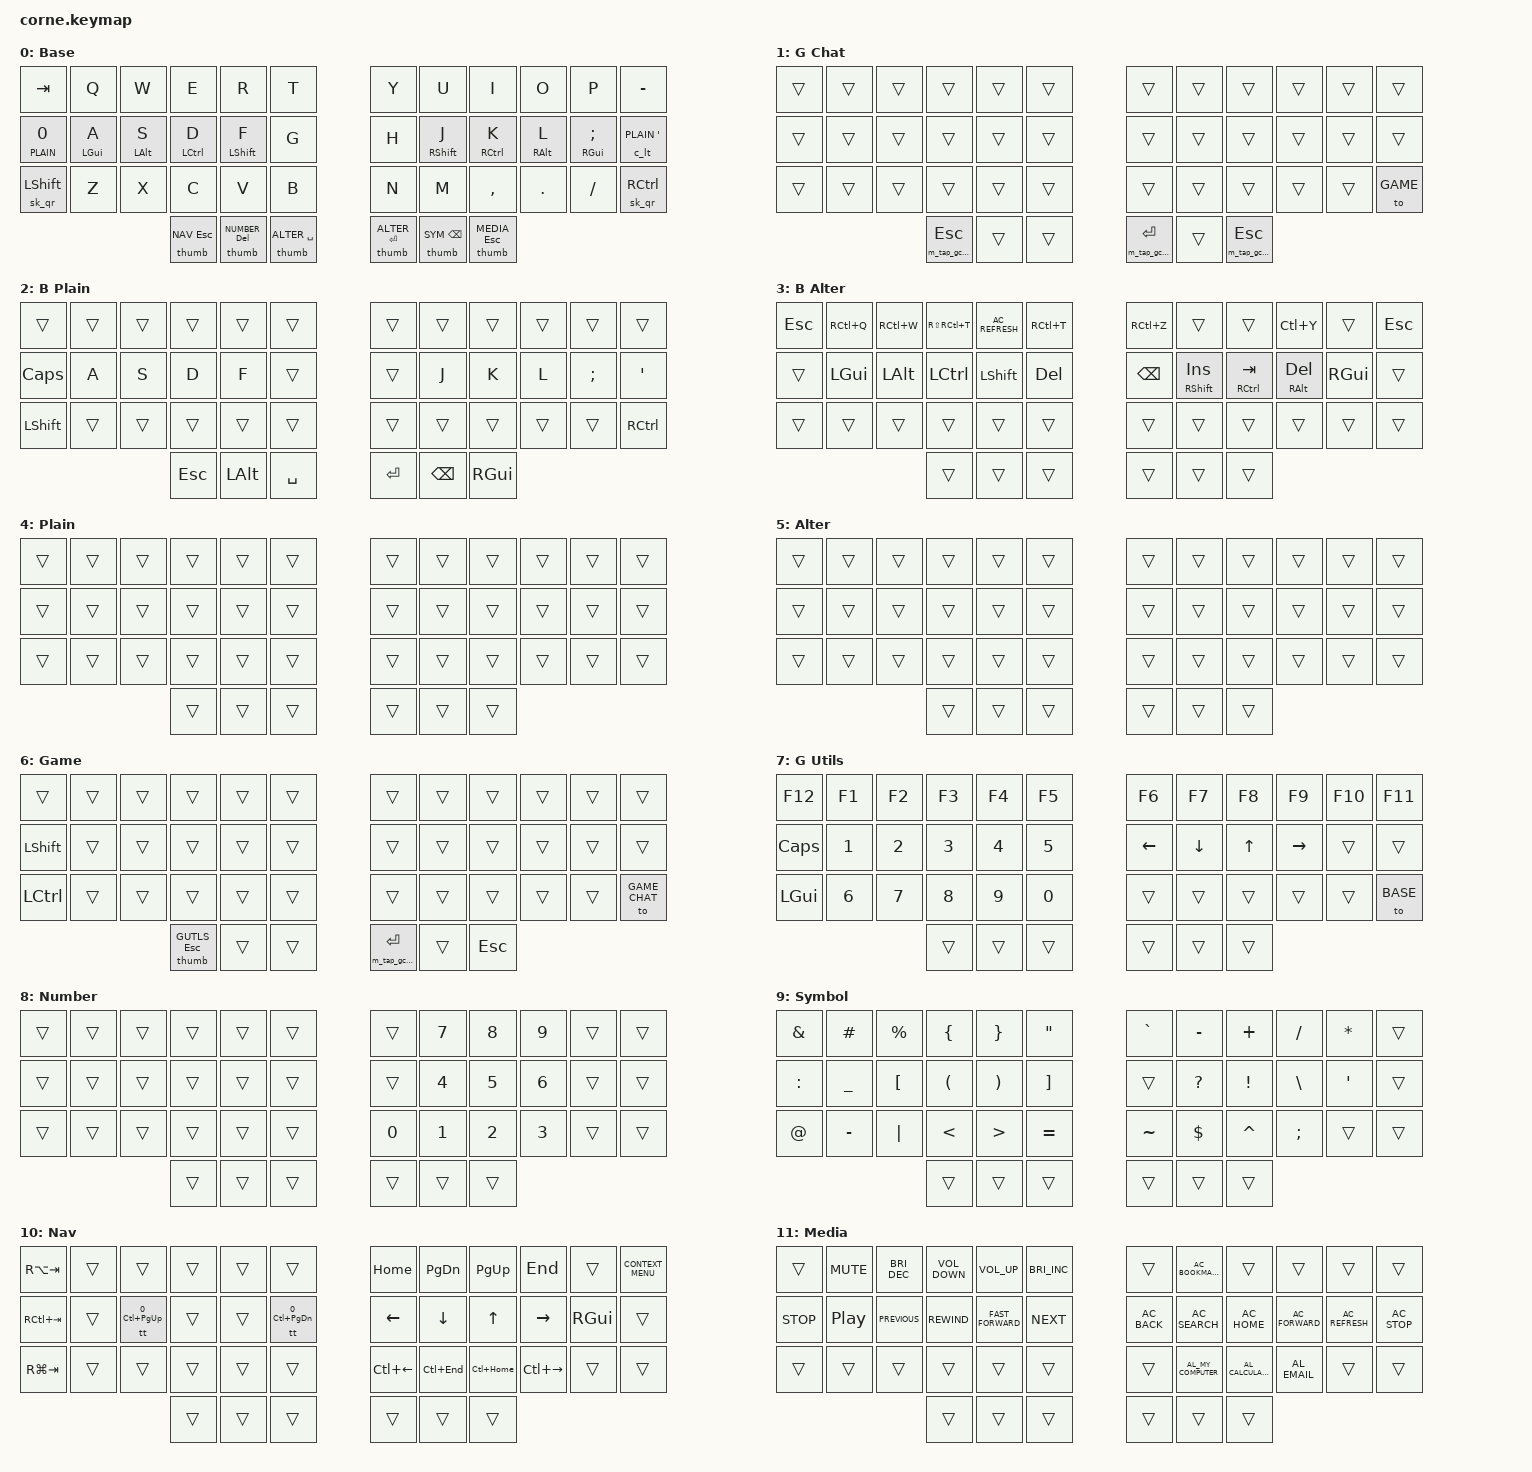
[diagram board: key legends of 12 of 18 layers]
/*
 * Copyright (c) 2020 The ZMK Contributors
 *
 * SPDX-License-Identifier: MIT
 */

#include <behaviors.dtsi>
#include <dt-bindings/zmk/keys.h>
#include <dt-bindings/zmk/bt.h>

#include "includes/constants.dtsi"
#include "includes/helpers.dtsi"

#include "fragments/macros.dtsi"
#include "fragments/behaviors.dtsi"
#include "fragments/combos.dtsi"
#include "fragments/conditional_layers.dtsi"

// Keymap template
//         template_layer {
//             display-name = "Temp";
// // -----------------------------------------------------------------------------------
// // |  ___ | ___ | ___ | ___ | ___ | ___ |       | ___ | ___ | ___ | ___ | ___ | ___  |
// // |  ___ | ___ | ___ | ___ | ___ | ___ |       | ___ | ___ | ___ | ___ | ___ | ___  |
// // |  ___ | ___ | ___ | ___ | ___ | ___ |       | ___ | ___ | ___ | ___ | ___ | ___  |
// //                    | ___ | ___ | ___ |       | ___ | ___ | ___ |
//             bindings = <
// &trans                 &trans                 &trans                 &trans                 &trans                 &trans                           &trans                 &trans                 &trans                 &trans                 &trans                 &trans
// &trans                 &trans                 &trans                 &trans                 &trans                 &trans                           &trans                 &trans                 &trans                 &trans                 &trans                 &trans
// &trans                 &trans                 &trans                 &trans                 &trans                 &trans                           &trans                 &trans                 &trans                 &trans                 &trans                 &trans
//                                                                      &trans                 &trans                 &trans                           &trans                 &trans                 &trans
//             >;
//         };

/ {
    keymap {
        compatible = "zmk,keymap";

        default_layer {
            display-name = "Base";
// -----------------------------------------------------------------------------------
// |  TAB |  Q  |  W  |  E  |  R  |  T  |       |  Y  |  U  |  I  |  O  |  P  |  -   |
// |  CAP |  A  |  S  |  D  |  F  |  G  |       |  H  |  J  |  K  |  L  |  ;  |  '   |
// |  SFT |  Z  |  X  |  C  |  V  |  B  |       |  N  |  M  |  ,  |  .  |  /  | CTL  |
//                    | ESC | DEL | SPC |       | RET | BSP | ESC |
            bindings = <
&kp TAB                &kp Q                  &kp W                  &kp E                  &kp R                  &kp T                            &kp Y                  &kp U                  &kp I                  &kp O                  &kp P                  &kp MINUS
&lt_cw PLAIN 0         &hrm_l LGUI A          &hrm_l LALT S          &hrm_l LCTRL D         &hrm_li LSHFT F        &kp G                            &kp H                  &hrm_ri RSHFT J        &hrm_r RCTRL K         &hrm_r RALT L          &hrm_r RGUI SEMICOLON  &c_lt PLAIN SINGLE_QUOTE
&sk_qr LEFT_SHIFT      &kp Z                  &kp X                  &kp C                  &kp V                  &kp B                            &kp N                  &kp M                  &kp COMMA              &kp PERIOD             &kp SLASH              &sk_qr RIGHT_CONTROL
                                                                     &thumb NAV ESCAPE      &thumb NUMBER DELETE   &thumb ALTER SPACE               &thumb ALTER RETURN    &thumb SYM BACKSPACE   &thumb MEDIA ESCAPE
            >;
        };

        game_chat_layer {
            display-name = "G Chat";
// -----------------------------------------------------------------------------------
// |  ___ | ___ | ___ | ___ | ___ | ___ |       | ___ | ___ | ___ | ___ | ___ | ___  |
// |  ___ | ___ | ___ | ___ | ___ | ___ |       | ___ | ___ | ___ | ___ | ___ | ___  |
// |  ___ | ___ | ___ | ___ | ___ | ___ |       | ___ | ___ | ___ | ___ | ___ | GAME |
//                    | ESC | ___ | ___ |       | RET | ___ | ESC |
            bindings = <
&trans                 &trans                 &trans                 &trans                 &trans                 &trans                           &trans                 &trans                 &trans                 &trans                 &trans                 &trans
&trans                 &trans                 &trans                 &trans                 &trans                 &trans                           &trans                 &trans                 &trans                 &trans                 &trans                 &trans
&trans                 &trans                 &trans                 &trans                 &trans                 &trans                           &trans                 &trans                 &trans                 &trans                 &trans                 &to GAME
                                                                     &m_tap_gchat_c ESCAPE  &trans                 &trans                           &m_tap_gchat_c RETURN  &trans                 &m_tap_gchat_c ESCAPE
            >;
        };

        base_plain_layer {
            display-name = "B Plain";
// -----------------------------------------------------------------------------------
// |  ___ | ___ | ___ | ___ | ___ | ___ |       | ___ | ___ | ___ | ___ | ___ | ___  |
// |  CAP |  A  |  S  |  D  |  F  | ___ |       | ___ |  J  |  K  |  L  |  ;  |  '   |
// |  SFT | ___ | ___ | ___ | ___ | ___ |       | ___ | ___ | ___ | ___ | ___ | CTL  |
//                    | ESC | ALT | SPC |       | RET | BSP | GUI |
            bindings = <
&trans                 &trans                 &trans                 &trans                 &trans                 &trans                           &trans                 &trans                 &trans                 &trans                 &trans                 &trans
&kp CAPSLOCK           &kp A                  &kp S                  &kp D                  &kp F                  &trans                           &trans                 &kp J                  &kp K                  &kp L                  &kp SEMICOLON          &kp SINGLE_QUOTE
&kp LEFT_SHIFT         &trans                 &trans                 &trans                 &trans                 &trans                           &trans                 &trans                 &trans                 &trans                 &trans                 &kp RIGHT_CONTROL
                                                                     &kp ESCAPE             &kp LEFT_ALT           &kp SPACE                        &kp RETURN             &kp BACKSPACE          &kp RIGHT_GUI
            >;
        };

        base_alter_layer {
            display-name = "B Alter";
// -----------------------------------------------------------------------------------
// |  ESC | QUT | CLS | RTB | REF | NTB |       | UND | ___ | ___ | RED | ___ | ESC  |
// |  ___ | GUI | ALT | CTL | SFT | DEL |       | BSP | INS | TAB | DEL | GUI | ___  |
// |  ___ | ___ | ___ | ___ | ___ | ___ |       | ___ | ___ | ___ | ___ | ___ | ___  |
//                    | ___ | ___ | ___ |       | ___ | ___ | ___ |
            bindings = <
&kp ESCAPE             &kp RC(Q)              &kp RC(W)              &kp RS(RC(T))          &kp C_AC_REFRESH       &kp RC(T)                        &kp RC(Z)              &trans                 &trans                 &kp LC(Y)              &trans                 &kp ESCAPE
&trans                 &kp LEFT_GUI           &kp LEFT_ALT           &kp LEFT_CONTROL       &kp LEFT_SHIFT         &kp DELETE                       &kp BACKSPACE          &hrm_ri RSHFT INSERT   &hrm_r RCTRL TAB       &hrm_r RALT DELETE     &kp RIGHT_GUI          &trans
&trans                 &trans                 &trans                 &trans                 &trans                 &trans                           &trans                 &trans                 &trans                 &trans                 &trans                 &trans
                                                                     &trans                 &trans                 &trans                           &trans                 &trans                 &trans
            >;
        };

        plain_layer {
            display-name = "Plain";
// -----------------------------------------------------------------------------------
// |  ___ | ___ | ___ | ___ | ___ | ___ |       | ___ | ___ | ___ | ___ | ___ | ___  |
// |  ___ | ___ | ___ | ___ | ___ | ___ |       | ___ | ___ | ___ | ___ | ___ | ___  |
// |  ___ | ___ | ___ | ___ | ___ | ___ |       | ___ | ___ | ___ | ___ | ___ | ___  |
//                    | ___ | ___ | ___ |       | ___ | ___ | ___ |
            bindings = <
&trans                 &trans                 &trans                 &trans                 &trans                 &trans                           &trans                 &trans                 &trans                 &trans                 &trans                 &trans
&trans                 &trans                 &trans                 &trans                 &trans                 &trans                           &trans                 &trans                 &trans                 &trans                 &trans                 &trans
&trans                 &trans                 &trans                 &trans                 &trans                 &trans                           &trans                 &trans                 &trans                 &trans                 &trans                 &trans
                                                                     &trans                 &trans                 &trans                           &trans                 &trans                 &trans
            >;
        };

        alter_layer {
            display-name = "Alter";
// -----------------------------------------------------------------------------------
// |  ___ | ___ | ___ | ___ | ___ | ___ |       | ___ | ___ | ___ | ___ | ___ | ___  |
// |  ___ | ___ | ___ | ___ | ___ | ___ |       | ___ | ___ | ___ | ___ | ___ | ___  |
// |  ___ | ___ | ___ | ___ | ___ | ___ |       | ___ | ___ | ___ | ___ | ___ | ___  |
//                    | ___ | ___ | ___ |       | ___ | ___ | ___ |
            bindings = <
&trans                 &trans                 &trans                 &trans                 &trans                 &trans                           &trans                 &trans                 &trans                 &trans                 &trans                 &trans
&trans                 &trans                 &trans                 &trans                 &trans                 &trans                           &trans                 &trans                 &trans                 &trans                 &trans                 &trans
&trans                 &trans                 &trans                 &trans                 &trans                 &trans                           &trans                 &trans                 &trans                 &trans                 &trans                 &trans
                                                                     &trans                 &trans                 &trans                           &trans                 &trans                 &trans
            >;
        };

        game_layer {
            display-name = "Game";
// -----------------------------------------------------------------------------------
// |  ___ | ___ | ___ | ___ | ___ | ___ |       | ___ | ___ | ___ | ___ | ___ | ___  |
// |  SFT | ___ | ___ | ___ | ___ | ___ |       | ___ | ___ | ___ | ___ | ___ | ___  |
// |  CTL | ___ | ___ | ___ | ___ | ___ |       | ___ | ___ | ___ | ___ | ___ | CHAT |
//                    | ESC | ___ | ___ |       | RET | ___ | ESC |
            bindings = <
&trans                 &trans                 &trans                 &trans                 &trans                 &trans                           &trans                 &trans                 &trans                 &trans                 &trans                 &trans
&kp LEFT_SHIFT         &trans                 &trans                 &trans                 &trans                 &trans                           &trans                 &trans                 &trans                 &trans                 &trans                 &trans
&kp LEFT_CONTROL       &trans                 &trans                 &trans                 &trans                 &trans                           &trans                 &trans                 &trans                 &trans                 &trans                 &to GAME_CHAT
                                                                     &thumb GUTLS ESCAPE    &trans                 &trans                           &m_tap_gchat_o RETURN  &trans                 &kp ESCAPE
            >;
        };

        game_utils_layer {
            display-name = "G Utils";
// -----------------------------------------------------------------------------------
// |  F12 | F1  | F2  | F3  | F4  | F5  |       | F6  | F7  | F8  | F9  | F10 | F11  |
// |  CAP |  1  |  2  |  3  |  4  |  5  |       |  ←  |  ↓  |  ↑  |  →  | ___ | ___  |
// |  GUI |  6  |  7  |  8  |  9  |  0  |       | ___ | ___ | ___ | ___ | ___ | BASE |
//                    | ___ | ___ | ___ |       | ___ | ___ | ___ |
            bindings = <
&kp F12                &kp F1                 &kp F2                 &kp F3                 &kp F4                 &kp F5                           &kp F6                 &kp F7                 &kp F8                 &kp F9                 &kp F10                &kp F11
&kp CAPSLOCK           &kp N1                 &kp N2                 &kp N3                 &kp N4                 &kp N5                           &kp LEFT               &kp DOWN               &kp UP                 &kp RIGHT              &trans                 &trans
&kp LEFT_GUI           &kp N6                 &kp N7                 &kp N8                 &kp N9                 &kp N0                           &trans                 &trans                 &trans                 &trans                 &trans                 &to BASE
                                                                     &trans                 &trans                 &trans                           &trans                 &trans                 &trans
            >;
        };

        number_layer {
            display-name = "Number";
// -----------------------------------------------------------------------------------
// |  ___ | ___ | ___ | ___ | ___ | ___ |       | ___ |  7  |  8  |  9  | ___ | ___  |
// |  ___ | ___ | ___ | ___ | ___ | ___ |       | ___ |  4  |  5  |  6  | ___ | ___  |
// |  ___ | ___ | ___ | ___ | ___ | ___ |       |  0  |  1  |  2  |  3  | ___ | ___  |
//                    | ___ | ___ | ___ |       | ___ | ___ | ___ |
            bindings = <
&trans                 &trans                 &trans                 &trans                 &trans                 &trans                           &trans                 &kp N7                 &kp N8                 &kp N9                 &trans                 &trans
&trans                 &trans                 &trans                 &trans                 &trans                 &trans                           &trans                 &kp N4                 &kp N5                 &kp N6                 &trans                 &trans
&trans                 &trans                 &trans                 &trans                 &trans                 &trans                           &kp N0                 &kp N1                 &kp N2                 &kp N3                 &trans                 &trans
                                                                     &trans                 &trans                 &trans                           &trans                 &trans                 &trans
            >;
        };

        symbol_layer {
            display-name = "Symbol";
// -----------------------------------------------------------------------------------
// |   &  |  #  |  %  |  {  |  }  |  "  |       |  `  |  -  |  +  |  /  |  *  | ___  |
// |   :  |  _  |  [  |  (  |  )  |  ]  |       | ___ |  ?  |  !  |  \  |  '  | ___  |
// |   @  |  -  |  |  |  <  |  >  |  =  |       |  ~  |  $  |  ^  |  ;  | ___ | ___  |
//                    | ___ | ___ | ___ |       | ___ | ___ | ___ |
            bindings = <
&kp AMPERSAND          &kp HASH               &kp PERCENT            &kp LEFT_BRACE         &kp RIGHT_BRACE        &kp DOUBLE_QUOTES                &kp GRAVE              &kp MINUS              &kp PLUS               &kp SLASH              &kp ASTERISK           &trans
&kp COLON              &kp UNDERSCORE         &kp LEFT_BRACKET       &kp LEFT_PARENTHESIS   &kp RIGHT_PARENTHESIS  &kp RIGHT_BRACKET                &trans                 &kp QUESTION           &kp EXCLAMATION        &kp BACKSLASH          &kp SINGLE_QUOTE       &trans
&kp AT_SIGN            &kp MINUS              &kp PIPE               &kp LESS_THAN          &kp GREATER_THAN       &kp EQUAL                        &kp TILDE              &kp DOLLAR             &kp CARET              &kp SEMICOLON          &trans                 &trans
                                                                     &trans                 &trans                 &trans                           &trans                 &trans                 &trans
            >;
        };

        navigation_layer {
            display-name = "Nav";
// -----------------------------------------------------------------------------------
// |  A → | ___ | ___ | ___ | ___ | ___ |       | HOM | PDN | PUP | END | ___ | CMN  |
// |  C → | ___ | T ← | ___ | ___ | T → |       |  ←  |  ↓  |  ↑  |  →  | GUI | ___  |
// |  G → | ___ | ___ | ___ | ___ | ___ |       | W ← | W ↓ | W ↑ | W → | ___ | ___  |
//                    | ___ | ___ | ___ |       | ___ | ___ | ___ |
            bindings = <
&kp RA(TAB)            &trans                 &trans                 &trans                 &trans                 &trans                           &kp HOME               &kp PAGE_DOWN          &kp PAGE_UP            &kp END                &trans                 &kp K_CONTEXT_MENU
&kp RC(TAB)            &trans                 &tt 0 LC(PAGE_UP)      &trans                 &trans                 &tt 0 LC(PAGE_DOWN)              &kp LEFT               &kp DOWN               &kp UP                 &kp RIGHT              &kp RIGHT_GUI          &trans
&kp RG(TAB)            &trans                 &trans                 &trans                 &trans                 &trans                           &kp LC(LEFT)           &kp LC(END)            &kp LC(HOME)           &kp LC(RIGHT)          &trans                 &trans
                                                                     &trans                 &trans                 &trans                           &trans                 &trans                 &trans
            >;
        };

        media_layer {
            display-name = "Media";
// -----------------------------------------------------------------------------------
// |  ___ | MUT | BDE | VDN | VUP | BIN |       | ___ | BMR | ___ | ___ | ___ | ___  |
// |  STP | PLP | PRV | RWD | FFW | NXT |       | BCK | SCH | HOM | FWD | REF | STP  |
// |  ___ | ___ | ___ | ___ | ___ | ___ |       | ___ | COM | CAL | MAI | ___ | ___  |
//                    | ___ | ___ | ___ |       | ___ | ___ | ___ |
            bindings = <
&trans                 &kp C_MUTE             &kp C_BRIGHTNESS_DEC   &kp C_VOLUME_DOWN      &kp C_VOLUME_UP        &kp C_BRIGHTNESS_INC             &trans                 &kp C_AC_BOOKMARKS     &trans                 &trans                 &trans                 &trans
&kp C_STOP             &kp C_PLAY_PAUSE       &kp C_PREVIOUS         &kp C_REWIND           &kp C_FAST_FORWARD     &kp C_NEXT                       &kp C_AC_BACK          &kp C_AC_SEARCH        &kp C_AC_HOME          &kp C_AC_FORWARD       &kp C_AC_REFRESH       &kp C_AC_STOP
&trans                 &trans                 &trans                 &trans                 &trans                 &trans                           &trans                 &kp C_AL_MY_COMPUTER   &kp C_AL_CALCULATOR    &kp C_AL_EMAIL         &trans                 &trans
                                                                     &trans                 &trans                 &trans                           &trans                 &trans                 &trans
            >;
        };

        numpad_layer {
            display-name = "Numpad";
// -----------------------------------------------------------------------------------
// |  ___ | ___ | ___ | ___ | ___ | ___ |       | NUM |  7  |  8  |  9  |  /  |  *   |
// |  ___ | ___ | ___ | ___ | ___ | ___ |       | ___ |  4  |  5  |  6  |  -  |  +   |
// |  ___ | ___ | ___ | ___ | ___ | ___ |       |  0  |  1  |  2  |  3  |  .  | ENT  |
//                    | ___ | ___ | ___ |       | ___ | ___ | ___ |
            bindings = <
&trans                 &trans                 &trans                 &trans                 &trans                 &trans                           &kp KP_NUMLOCK         &kp KP_N7              &kp KP_N8              &kp KP_N9              &kp KP_DIVIDE          &kp KP_MULTIPLY
&trans                 &trans                 &trans                 &trans                 &trans                 &trans                           &trans                 &kp KP_N4              &kp KP_N5              &kp KP_N6              &kp KP_MINUS           &kp KP_PLUS
&trans                 &trans                 &trans                 &trans                 &trans                 &trans                           &kp KP_N0              &kp KP_N1              &kp KP_N2              &kp KP_N3              &kp KP_DOT             &kp KP_ENTER
                                                                     &trans                 &trans                 &trans                           &trans                 &trans                 &trans
            >;
        };

        macro_layer {
            display-name = "Macro";
// -----------------------------------------------------------------------------------
// |  ___ | #{} | %{} | {}  | ___ |"#{}"|       | ___ | ___ | ___ | ___ | ___ | ___  |
// |  ::  | ___ | []  | ()  | SFT | ___ |       | ___ | SFT | ___ | ___ | ___ | ___  |
// | @spec| <-> | <|> | <<>>| ___ | <=> |       | <~> | ___ | ___ | ___ | ___ | ___  |
//                    | ___ | ___ | ___ |       | ___ | ___ | ___ |
            bindings = <
&trans                 &m_ex_interp           &m_ex_map              &m_braces              &trans                 &m_ex_full_interp                &trans                 &trans                 &trans                 &trans                 &trans                 &trans
&m_ex_type_delim       &trans                 &m_brackets            &m_parens              &kp LEFT_SHIFT         &trans                           &trans                 &kp RIGHT_SHIFT        &trans                 &trans                 &trans                 &trans
&mm_ex_specs           &mm_arrows             &mm_pipes              &mm_chevrons           &trans                 &mm_fat_arrows                   &mm_tilde_arrows       &trans                 &trans                 &trans                 &trans                 &trans
                                                                     &trans                 &trans                 &trans                           &trans                 &trans                 &trans
            >;
        };

        sysutils_layer {
            display-name = "Sysutils";
// -----------------------------------------------------------------------------------
// |  ___ | ___ | ___ | ___ | ___ | ___ |       | F12 | F7  | F8  | F9  | ___ | PBR  |
// |  CAP | GUI | ALT | CTL | SFT | ___ |       | F11 | F4  | F5  | F6  | ___ | PSC  |
// |  ___ | ___ | ___ | ___ | ___ | ___ |       | F10 | F1  | F2  | F3  | ___ | SLC  |
//                    | ___ | ___ | ___ |       | ___ | ___ | ___ |
            bindings = <
&trans                 &trans                 &trans                 &trans                 &trans                 &trans                           &kp F12                &kp F7                 &kp F8                 &kp F9                 &trans                 &kp PAUSE_BREAK
&kp CAPSLOCK           &kp LEFT_GUI           &kp LEFT_ALT           &kp LEFT_CONTROL       &kp LEFT_SHIFT         &trans                           &kp F11                &kp F4                 &kp F5                 &kp F6                 &trans                 &kp PRINTSCREEN
&trans                 &trans                 &trans                 &trans                 &trans                 &trans                           &kp F10                &kp F1                 &kp F2                 &kp F3                 &trans                 &kp SCROLLLOCK
                                                                     &trans                 &trans                 &trans                           &trans                 &trans                 &trans
            >;
        };

        system_layer {
            display-name = "System";
// -----------------------------------------------------------------------------------
// |  PWR | ___ | ___ | ___ | ___ | ___ |       | ___ | ___ | ___ | ___ | ___ | PWR  |
// |  SLP | ___ | ___ | ___ | ___ | ___ |       | LOF | LOC | ___ | ___ | ___ | SLP  |
// |  RES | ___ | ___ | ___ | ___ | ___ |       | ___ | ___ | ___ | ___ | ___ | RES  |
//                    | ___ | ___ | ___ |       | ___ | ___ | ___ |
            bindings = <
&kp C_POWER            &trans                 &trans                 &trans                 &trans                 &trans                           &trans                 &trans                 &trans                 &trans                 &trans                 &kp C_POWER
&kp C_SLEEP            &trans                 &trans                 &trans                 &trans                 &trans                           &kp C_AL_LOGOFF        &kp C_AL_LOCK          &trans                 &trans                 &trans                 &kp C_SLEEP
&kp C_RESET            &trans                 &trans                 &trans                 &trans                 &trans                           &trans                 &trans                 &trans                 &trans                 &trans                 &kp C_RESET
                                                                     &trans                 &trans                 &trans                           &trans                 &trans                 &trans
            >;
        };

        bluetooth_layer {
            display-name = "BT";
// -----------------------------------------------------------------------------------
// |  ___ | ___ | BTP | ___ | ___ | BTN |       | ___ | ___ | ___ | ___ | ___ | ___  |
// | BCLR | BT1 | BT2 | BT3 | BT4 | BT5 |       | ___ | ___ | ___ | ___ | ___ | ___  |
// | BRES | BD1 | BD2 | BD3 | BD4 | BD5 |       | ___ | ___ | ___ | ___ | ___ | ___  |
//                    | ___ | ___ | ___ |       | ___ | ___ | ___ |
            bindings = <
&trans                 &trans                 &bt BT_PRV             &trans                 &trans                 &bt BT_NXT                       &trans                 &trans                 &trans                 &trans                 &trans                 &trans
&bt BT_CLR             &bt BT_SEL 0           &bt BT_SEL 1           &bt BT_SEL 2           &bt BT_SEL 3           &bt BT_SEL 4                     &trans                 &trans                 &trans                 &trans                 &trans                 &trans
&bt BT_CLR_ALL         &bt BT_DISC 0          &bt BT_DISC 1          &bt BT_DISC 2          &bt BT_DISC 3          &bt BT_DISC 4                    &trans                 &trans                 &trans                 &trans                 &trans                 &trans
                                                                     &trans                 &trans                 &trans                           &trans                 &trans                 &trans
            >;
        };

        keysys_layer {
            display-name = "Keysys";
// -----------------------------------------------------------------------------------
// |  BLD | ___ | ___ | ___ | ___ | ___ |       | ___ | ___ | ___ | ___ | ___ | BLD  |
// |  ULC | ___ | GAM | PLN | BAS | ___ |       | ___ | BAS | PLN | GAM | ___ | ULC  |
// |  RES | ___ | ___ | ___ | ___ | ___ |       | ___ | ___ | ___ | ___ | ___ | RES  |
//                    | ___ | ___ | ___ |       | ___ | ___ | ___ |
            bindings = <
&bootloader            &trans                 &trans                 &trans                 &trans                 &trans                           &trans                 &trans                 &trans                 &trans                 &trans                 &bootloader
&studio_unlock         &trans                 &to GAME               &to PLAIN              &to BASE               &trans                           &trans                 &to BASE               &to PLAIN              &to GAME               &trans                 &studio_unlock
&sys_reset             &trans                 &trans                 &trans                 &trans                 &trans                           &trans                 &trans                 &trans                 &trans                 &trans                 &sys_reset
                                                                     &trans                 &trans                 &trans                           &trans                 &trans                 &trans
            >;
        };

        sandbox_layer {
            display-name = "Sandbox";
            status = "reserved";
        };
    };
};
